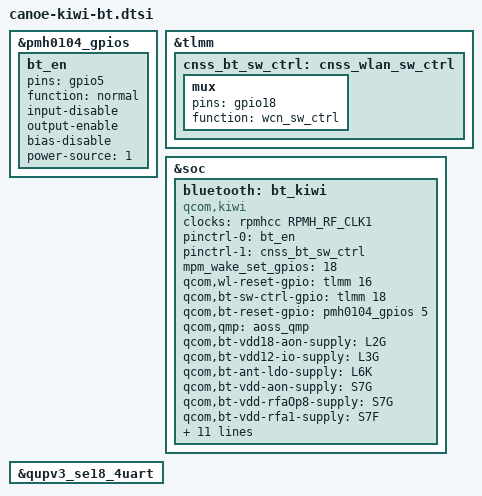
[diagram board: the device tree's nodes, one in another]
// SPDX-License-Identifier: BSD-3-Clause

/*
 * Copyright (c) 2024 Qualcomm Innovation Center, Inc. All rights reserved.
 */

#include <dt-bindings/interconnect/qcom,canoe.h>
#include <dt-bindings/clock/qcom,rpmh.h>

&pmh0104_gpios {
	bt_en: bt_en {
		pins = "gpio5";
		function = "normal";
		input-disable;
		output-enable;
		bias-disable;
		power-source = <1>;
	};
};

&tlmm {
	cnss_bt_sw_ctrl: cnss_wlan_sw_ctrl {
		mux {
			pins = "gpio18";
			function = "wcn_sw_ctrl";
		};
	};
};

&soc {
	bluetooth: bt_kiwi {
			compatible = "qcom,kiwi";

			clocks = <&rpmhcc RPMH_RF_CLK1>;
			clock-names = "bt_rf_clk1";
			pinctrl-names = "bt_en", "sw_ctrl";
			pinctrl-0 = <&bt_en>;
			pinctrl-1 = <&cnss_bt_sw_ctrl>;
			/* List of GPIOs to be setup for interrupt wakeup capable*/
			mpm_wake_set_gpios = <18>;
			qcom,wl-reset-gpio = <&tlmm 16 0>; /* WL_EN */
			qcom,bt-sw-ctrl-gpio = <&tlmm 18 0>; /* SW_CTRL */
			qcom,bt-reset-gpio = <&pmh0104_gpios 5 0>; /* BT_EN */
			qcom,qmp = <&aoss_qmp>;

			qcom,bt-vdd18-aon-supply  = <&L2G>;  /* BT VDD1.8 AON */
			qcom,bt-vdd12-io-supply   = <&L3G>;  /* BT VDD1.2V IO */
			qcom,bt-ant-ldo-supply    = <&L6K>;  /* BT ANT - AV91C_VDD */
			qcom,bt-vdd-aon-supply    = <&S7G>;  /* BT AON LDO*/
			qcom,bt-vdd-rfaOp8-supply = <&S7G>;  /* BT RFAOp8 CMN LDO*/
			qcom,bt-vdd-rfa1-supply   = <&S7F>;  /* BT RFA1.2 LDO */
			qcom,bt-vdd-rfa2-supply   = <&S8F>;  /* BT RFA1.8 LDO */

			qcom,bt-vdd18-aon-config  = <1800000 1800000 30000 1 0>;
			qcom,bt-vdd12-io-config   = <1200000 1200000 30000 1 0>;
			qcom,bt-ant-ldo-config    = <1800000 1860000 0 1 0>;
			qcom,bt-vdd-aon-config    = <916000 1100000 0 1 0>;
			qcom,bt-vdd-rfaOp8-config = <916000 1100000 0 1 0>;
			qcom,bt-vdd-rfa1-config   = <1316000 1340000 0 1 0>;
			qcom,bt-vdd-rfa2-config   = <1864000 2000000 0 1 0>;

			// TODO PDC TABLE  BUS BW

	};

};


//uart instance
&qupv3_se18_4uart {
	status = "ok";
};
